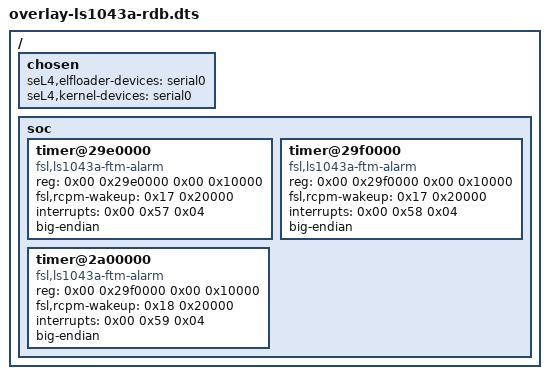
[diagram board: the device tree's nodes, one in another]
/*
 * Copyright 2020, Data61, CSIRO (ABN 41 687 119 230)
 *
 * SPDX-License-Identifier: GPL-2.0-only
 */

/ {
	chosen {
		seL4,elfloader-devices =
			"serial0",
			&{/timer};

		seL4,kernel-devices =
			"serial0",
            &{/interrupt-controller@1400000},
			&{/timer};
	};
    soc {
        timer@29e0000 {
            compatible = "fsl,ls1043a-ftm-alarm";
            reg = <0x00 0x29e0000 0x00 0x10000>;
            fsl,rcpm-wakeup = <0x17 0x20000>;
            interrupts = <0x00 0x57 0x04>;
            big-endian;
        };
        timer@29f0000 {
            compatible = "fsl,ls1043a-ftm-alarm";
            reg = <0x00 0x29f0000 0x00 0x10000>;
            fsl,rcpm-wakeup = <0x17 0x20000>;
            interrupts = <0x00 0x58 0x04>;
            big-endian;
        };
        timer@2a00000 {
            compatible = "fsl,ls1043a-ftm-alarm";
            reg = <0x00 0x29f0000 0x00 0x10000>;
            fsl,rcpm-wakeup = <0x18 0x20000>;
            interrupts = <0x00 0x59 0x04>;
            big-endian;
        };
    };
};
